# PIC32MX550F256L register map
Vendor: Microchip
Registers are 32-bit, read-write, reset 0x0 unless marked. A register's access mark holds for its fields unless they carry their own. Addresses are absolute, and some are shared; only a register's first bit layout is shown; [hi:lo] are bit positions; {n}, {i} and the like mark numbered series.

## UART4
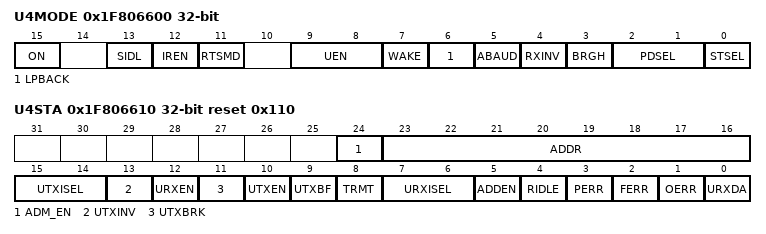
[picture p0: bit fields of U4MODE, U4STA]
0x1F806600 U4MODE
  [15] ON, [13] SIDL, [12] IREN, [11] RTSMD, [9:8] UEN, [7] WAKE, [6] LPBACK, [5] ABAUD, [4] RXINV, [3] BRGH, [2:1] PDSEL, [0] STSEL
0x1F806610 U4STA reset 0x110
  [24] ADM_EN
  [23:16] ADDR
  [15:14] UTXISEL
  [13] UTXINV
  [12] URXEN
  [11] UTXBRK
  [10] UTXEN
  [9] UTXBF ro
  [8] TRMT ro
  [7:6] URXISEL
  [5] ADDEN
  [4] RIDLE ro
  [3] PERR ro
  [2] FERR ro
  [1] OERR — (can only be cleared)
  [0] URXDA ro
0x1F806620 U4TXREG reset not defined — (power-on value -----------------------xxxxxxxxx)
  [8:0] U4TXREG
0x1F806630 U4RXREG ro
  [8:0] U4RXREG
0x1F806640 U4BRG
  [15:0] BRG

## UART5
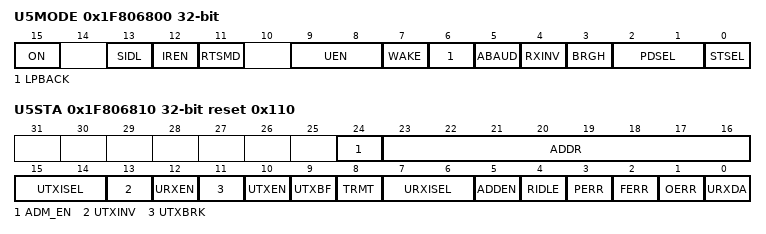
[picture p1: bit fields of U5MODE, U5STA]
0x1F806800 U5MODE
  [15] ON, [13] SIDL, [12] IREN, [11] RTSMD, [9:8] UEN, [7] WAKE, [6] LPBACK, [5] ABAUD, [4] RXINV, [3] BRGH, [2:1] PDSEL, [0] STSEL
0x1F806810 U5STA reset 0x110
  [24] ADM_EN
  [23:16] ADDR
  [15:14] UTXISEL
  [13] UTXINV
  [12] URXEN
  [11] UTXBRK
  [10] UTXEN
  [9] UTXBF ro
  [8] TRMT ro
  [7:6] URXISEL
  [5] ADDEN
  [4] RIDLE ro
  [3] PERR ro
  [2] FERR ro
  [1] OERR — (can only be cleared)
  [0] URXDA ro
0x1F806820 U5TXREG reset not defined — (power-on value -----------------------xxxxxxxxx)
  [8:0] U5TXREG
0x1F806830 U5RXREG ro
  [8:0] U5RXREG
0x1F806840 U5BRG
  [15:0] BRG

## PMP
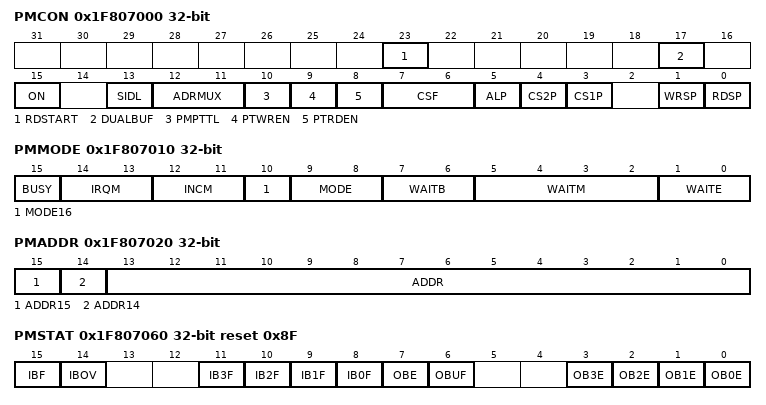
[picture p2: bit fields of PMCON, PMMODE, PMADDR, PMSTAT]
0x1F807000 PMCON reset not defined — (power-on value --------x-----x-00000-0000000-00)
  [23] RDSTART, [17] DUALBUF, [15] ON, [13] SIDL, [12:11] ADRMUX, [10] PMPTTL, [9] PTWREN, [8] PTRDEN, [7:6] CSF, [5] ALP, [4] CS2P, [3] CS1P, [1] WRSP, [0] RDSP
0x1F807010 PMMODE
  [15] BUSY, [14:13] IRQM, [12:11] INCM, [10] MODE16, [9:8] MODE, [7:6] WAITB, [5:2] WAITM, [1:0] WAITE
0x1F807020 PMADDR reset not defined — (power-on value ----------------xxxxxxxxxxxxxxxx)
  [15] ADDR15, [14] ADDR14, [13:0] ADDR
0x1F807030 PMDOUT reset not defined — (power-on value xxxxxxxxxxxxxxxxxxxxxxxxxxxxxxxx)
  [31:0] DATAOUT
0x1F807040 PMDIN reset not defined — (power-on value xxxxxxxxxxxxxxxxxxxxxxxxxxxxxxxx)
  [31:0] DATAIN
0x1F807050 PMAEN reset not defined — (power-on value --------xxxxxxxxxxxxxxxxxxxxxxxx)
  [23:0] PTEN
0x1F807060 PMSTAT reset 0x8F
  [15] IBF ro, [14] IBOV, [n+8] IB{n}F ro (n=0..3), [7] OBE ro, [6] OBUF, [n] OB{n}E ro (n=0..3)
0x1F807070 PMWADDR reset not defined — (power-on value --------xxxxxxxxxxxxxxxxxxxxxxxx)
  [23:0] WADDR
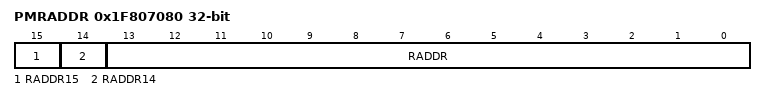
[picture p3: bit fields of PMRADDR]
0x1F807080 PMRADDR reset not defined — (power-on value ----------------xxxxxxxxxxxxxxxx)
  [15] RADDR15, [14] RADDR14, [13:0] RADDR
0x1F807090 PMRDIN reset not defined — (power-on value xxxxxxxxxxxxxxxxxxxxxxxxxxxxxxxx)
  [31:0] RDATAIN

## ADC10
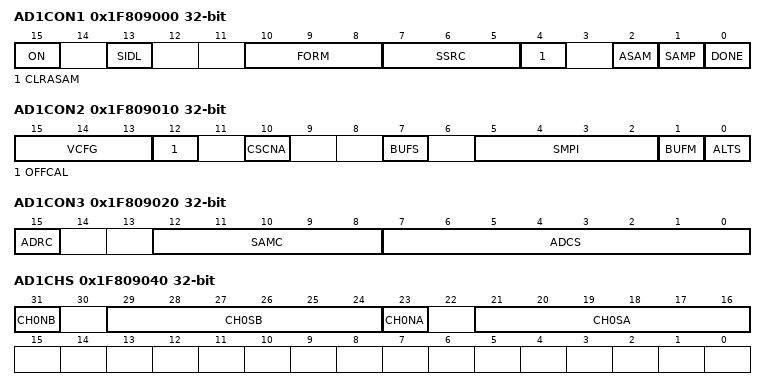
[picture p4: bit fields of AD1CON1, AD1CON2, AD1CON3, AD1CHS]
0x1F809000 AD1CON1
  [15] ON
  [13] SIDL
  [10:8] FORM
  [7:5] SSRC
  [4] CLRASAM
  [2] ASAM
  [1] SAMP
  [0] DONE — (can only be cleared)
0x1F809010 AD1CON2
  [15:13] VCFG, [12] OFFCAL, [10] CSCNA, [7] BUFS ro, [5:2] SMPI, [1] BUFM, [0] ALTS
0x1F809020 AD1CON3
  [15] ADRC, [12:8] SAMC, [7:0] ADCS
0x1F809040 AD1CHS reset not defined — (power-on value 0-xxxxxx0-xxxxxx----------------)
  [31] CH0NB, [29:24] CH0SB, [23] CH0NA, [21:16] CH0SA
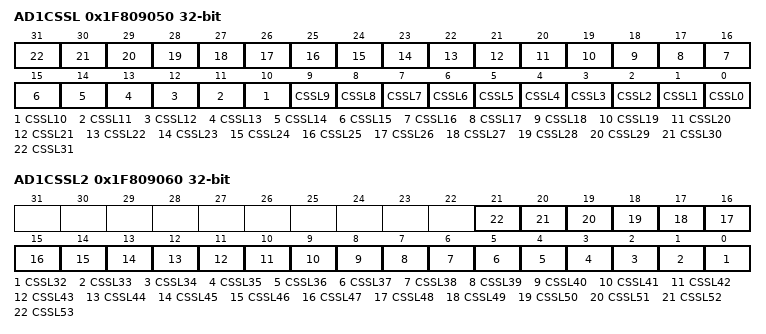
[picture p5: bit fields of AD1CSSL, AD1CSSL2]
0x1F809050 AD1CSSL reset not defined — (power-on value xxxxxxxxxxxxxxxxxxxxxxxxxxxxxxxx)
  [n] CSSL{n} (n=0..31)
0x1F809060 AD1CSSL2 reset not defined — (power-on value ----------xxxxxxxxxxxxxxxxxxxxxx)
  [n-32] CSSL{n} (n=32..53)
{0x1F809070+0x10*i} ADC1BUF{i} ro (i=0..9)
0x1F809110 ADC1BUFA ro
0x1F809120 ADC1BUFB ro
0x1F809130 ADC1BUFC ro
0x1F809140 ADC1BUFD ro
0x1F809150 ADC1BUFE ro
0x1F809160 ADC1BUFF ro

## CVR
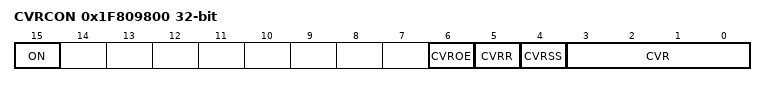
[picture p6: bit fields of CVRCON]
0x1F809800 CVRCON
  [15] ON, [6] CVROE, [5] CVRR, [4] CVRSS, [3:0] CVR

## CMP1
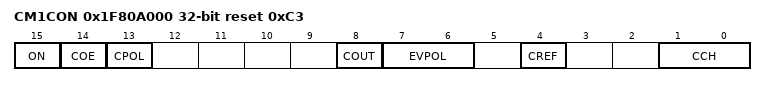
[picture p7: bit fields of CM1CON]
0x1F80A000 CM1CON reset 0xC3
  [15] ON, [14] COE, [13] CPOL, [8] COUT, [7:6] EVPOL, [4] CREF, [1:0] CCH
